# STM32L052 register map
File version: 1.0
CPU: CM0+ r0p0, little endian, MPU, no FPU, 4 interrupt priority bits
Registers are 32-bit, read-write, reset 0x0 unless marked. A register's access mark holds for its fields unless they carry their own. Offsets are from the block's base; [hi:lo] are bit positions; {n}, {i} and the like mark numbered series; 'fields as' and 'values as' point back to an identical list.

## DMA1 — Direct memory access controller
Base 0x40020000
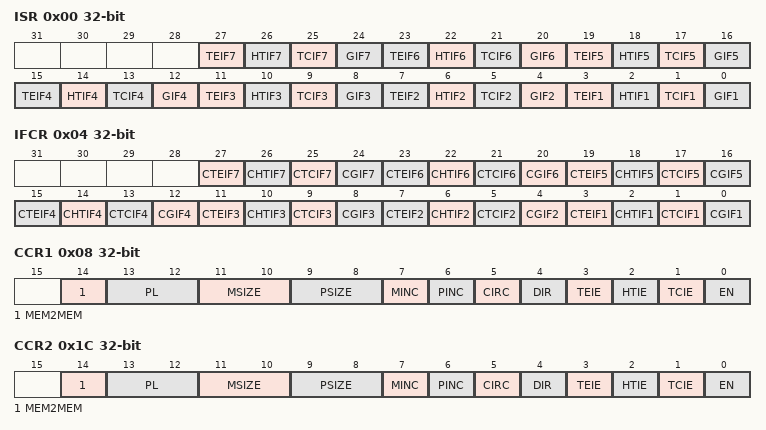
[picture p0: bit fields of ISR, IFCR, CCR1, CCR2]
0x00 ISR ro — interrupt status register
  [4n-1] TEIF{n} (n=1..7) — Channel x transfer error flag (x = 1 ..7)
  [4n-2] HTIF{n} (n=1..7) — Channel x half transfer flag (x = 1 ..7)
  [4n-3] TCIF{n} (n=1..7) — Channel x transfer complete flag (x = 1 ..7)
  [4n-4] GIF{n} (n=1..7) — Channel x global interrupt flag (x = 1 ..7)
0x04 IFCR wo — interrupt flag clear register
  [4n-1] CTEIF{n} (n=1..7) — Channel x transfer error clear (x = 1 ..7)
  [4n-2] CHTIF{n} (n=1..7) — Channel x half transfer clear (x = 1 ..7)
  [4n-3] CTCIF{n} (n=1..7) — Channel x transfer complete clear (x = 1 ..7)
  [4n-4] CGIF{n} (n=1..7) — Channel x global interrupt clear (x = 1 ..7)
0x08 CCR1 — channel x configuration register
  [14] MEM2MEM — Memory to memory mode
  [13:12] PL — Channel priority level
  [11:10] MSIZE — Memory size
  [9:8] PSIZE — Peripheral size
  [7] MINC — Memory increment mode
  [6] PINC — Peripheral increment mode
  [5] CIRC — Circular mode
  [4] DIR — Data transfer direction
  [3] TEIE — Transfer error interrupt enable
  [2] HTIE — Half transfer interrupt enable
  [1] TCIE — Transfer complete interrupt enable
  [0] EN — Channel enable
0x0C CNDTR1 — channel x number of data register
  [15:0] NDT — Number of data to transfer
0x10 CPAR1 — channel x peripheral address register
  [31:0] PA — Peripheral address
{0x0+0x14*i} CMAR{i} (i=1..7) — channel x memory address register
  [31:0] MA — Memory address
0x1C CCR2 — channel x configuration register
  fields as CCR1
0x20 CNDTR2 — channel x number of data register
  [15:0] NDT — Number of data to transfer
0x24 CPAR2 — channel x peripheral address register
  [31:0] PA — Peripheral address
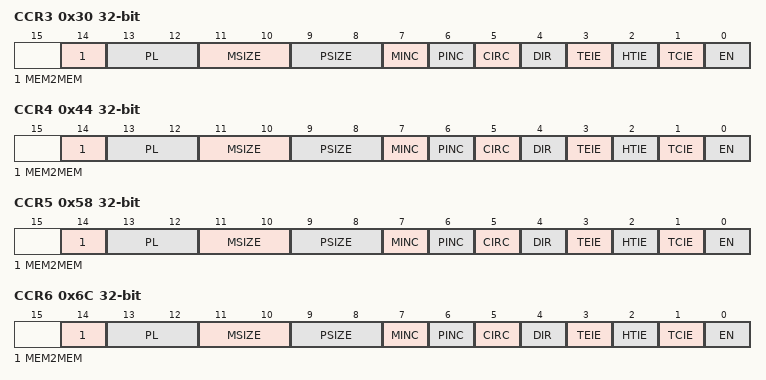
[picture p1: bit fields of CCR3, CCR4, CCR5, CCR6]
0x30 CCR3 — channel x configuration register
  fields as CCR1
0x34 CNDTR3 — channel x number of data register
  [15:0] NDT — Number of data to transfer
0x38 CPAR3 — channel x peripheral address register
  [31:0] PA — Peripheral address
0x44 CCR4 — channel x configuration register
  fields as CCR1
0x48 CNDTR4 — channel x number of data register
  [15:0] NDT — Number of data to transfer
0x4C CPAR4 — channel x peripheral address register
  [31:0] PA — Peripheral address
0x58 CCR5 — channel x configuration register
  fields as CCR1
0x5C CNDTR5 — channel x number of data register
  [15:0] NDT — Number of data to transfer
0x60 CPAR5 — channel x peripheral address register
  [31:0] PA — Peripheral address
0x6C CCR6 — channel x configuration register
  fields as CCR1
0x70 CNDTR6 — channel x number of data register
  [15:0] NDT — Number of data to transfer
0x74 CPAR6 — channel x peripheral address register
  [31:0] PA — Peripheral address
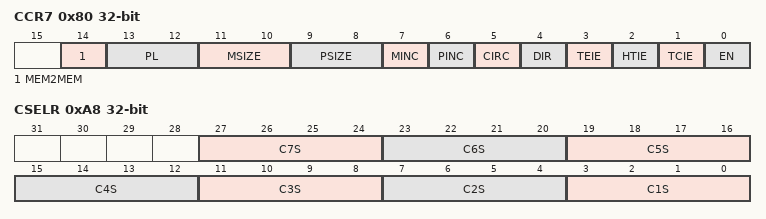
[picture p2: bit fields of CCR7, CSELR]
0x80 CCR7 — channel x configuration register
  fields as CCR1
0x84 CNDTR7 — channel x number of data register
  [15:0] NDT — Number of data to transfer
0x88 CPAR7 — channel x peripheral address register
  [31:0] PA — Peripheral address
0xA8 CSELR — channel selection register
  [4n-1:4n-4] C{n}S (n=1..7) — DMA channel {n} selection

## CRC — Cyclic redundancy check calculation unit
Base 0x40023000
0x00 DR reset 0xFFFFFFFF — Data register
  [31:0] DR — Data register bits
0x04 IDR — Independent data register
  [7:0] IDR — General-purpose 8-bit data register bits
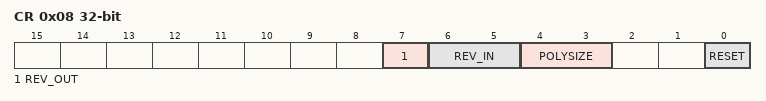
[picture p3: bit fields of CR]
0x08 CR access per field — Control register
  [7] REV_OUT rw — Reverse output data
  [6:5] REV_IN rw — Reverse input data
  [4:3] POLYSIZE rw — Polynomial size
  [0] RESET wo — RESET bit
0x10 INIT reset 0xFFFFFFFF — Initial CRC value
  [31:0] CRC_INIT — Programmable initial CRC value
0x14 POL reset 0x4C11DB7 — polynomial
  [31:0] Polynomialcoefficients — Programmable polynomial

## NVIC — Nested Vectored Interrupt Controller
Base 0xE000E100
0x00 ISER — Interrupt Set Enable Register
  [31:0] SETENA
0x80 ICER — Interrupt Clear Enable Register
  [31:0] CLRENA
0x100 ISPR — Interrupt Set-Pending Register
  [31:0] SETPEND
0x180 ICPR — Interrupt Clear-Pending Register
  [31:0] CLRPEND
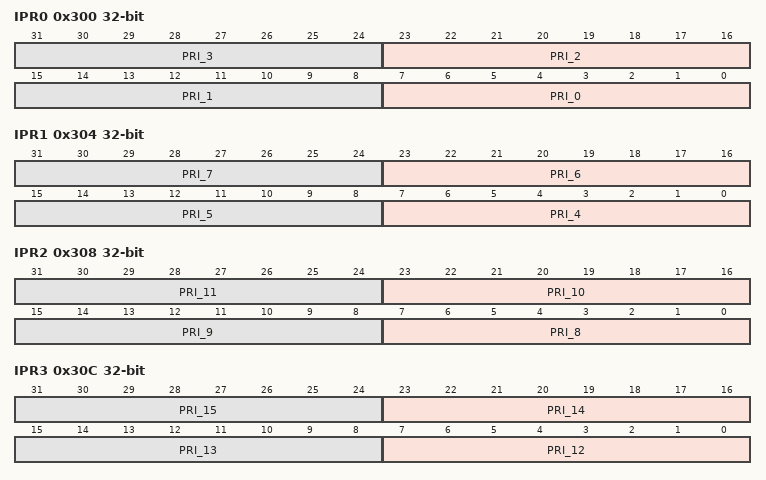
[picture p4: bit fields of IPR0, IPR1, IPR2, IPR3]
0x300 IPR0 — Interrupt Priority Register 0
  [8n+7:8n] PRI_{n} (n=0..3) — priority for interrupt {n}
0x304 IPR1 — Interrupt Priority Register 1
  [8n-25:8n-32] PRI_{n} (n=4..7) — priority for interrupt n
0x308 IPR2 — Interrupt Priority Register 2
  [8n-57:8n-64] PRI_{n} (n=8..11) — priority for interrupt n
0x30C IPR3 — Interrupt Priority Register 3
  [8n-89:8n-96] PRI_{n} (n=12..15) — priority for interrupt n
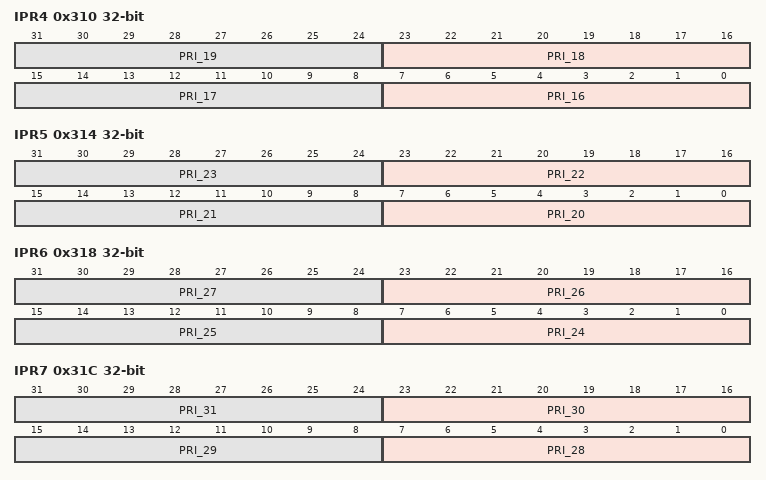
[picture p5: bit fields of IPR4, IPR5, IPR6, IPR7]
0x310 IPR4 — Interrupt Priority Register 4
  [8n-121:8n-128] PRI_{n} (n=16..19) — priority for interrupt n
0x314 IPR5 — Interrupt Priority Register 5
  [8n-153:8n-160] PRI_{n} (n=20..23) — priority for interrupt n
0x318 IPR6 — Interrupt Priority Register 6
  [8n-185:8n-192] PRI_{n} (n=24..27) — priority for interrupt n
0x31C IPR7 — Interrupt Priority Register 7
  [8n-217:8n-224] PRI_{n} (n=28..31) — priority for interrupt n
0x320 IPR8 — Interrupt Priority Register 8
